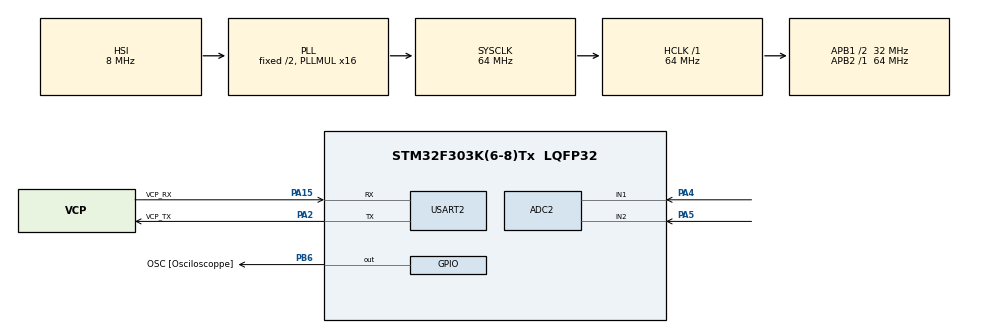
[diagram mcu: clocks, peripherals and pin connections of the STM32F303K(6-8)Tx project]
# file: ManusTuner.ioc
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ADC2.Channel-0\#ChannelRegularConversion=ADC_CHANNEL_1
ADC2.ContinuousConvMode=ENABLE
ADC2.DMAContinuousRequests=ENABLE
ADC2.NbrOfConversionFlag=1
ADC2.Offset-0\#ChannelRegularConversion=0
ADC2.OffsetNumber-0\#ChannelRegularConversion=ADC_OFFSET_NONE
ADC2.Rank-0\#ChannelRegularConversion=1
ADC2.SamplingTime-0\#ChannelRegularConversion=ADC_SAMPLETIME_61CYCLES_5
Dma.ADC2.0.Direction=DMA_PERIPH_TO_MEMORY
Dma.ADC2.0.Instance=DMA1_Channel2
Dma.ADC2.0.MemDataAlignment=DMA_MDATAALIGN_HALFWORD
Dma.ADC2.0.MemInc=DMA_MINC_ENABLE
Dma.ADC2.0.Mode=DMA_CIRCULAR
Dma.ADC2.0.PeriphDataAlignment=DMA_PDATAALIGN_HALFWORD
Dma.ADC2.0.PeriphInc=DMA_PINC_DISABLE
Dma.ADC2.0.Priority=DMA_PRIORITY_HIGH
Dma.Request0=ADC2
Mcu.Family=STM32F3
Mcu.Name=STM32F303K(6-8)Tx
Mcu.Package=LQFP32
NVIC.DMA1_Channel2_IRQn=true\:0\:0\:false\:false\:true\:false\:true
NVIC.PriorityGroup=NVIC_PRIORITYGROUP_4
PA13.GPIO_Label=SWDIO
PA13.Mode=Serial_Wire
PA13.Signal=SYS_JTMS-SWDIO
PA14.GPIO_Label=SWCLK
PA14.Mode=Serial_Wire
PA14.Signal=SYS_JTCK-SWCLK
PA15.GPIO_Label=VCP_RX
PA15.Mode=Asynchronous
PA15.Signal=USART2_RX
PA2.GPIO_Label=VCP_TX
PA2.Mode=Asynchronous
PA2.Signal=USART2_TX
PA4.Mode=IN1-Single-Ended
PA4.Signal=ADC2_IN1
PA5.Mode=IN2-Single-Ended
PA5.Signal=ADC2_IN2
PB6.GPIO_Label=OSC [Osciloscoppe]
PB6.Signal=GPIO_Output
PF0\ /\ OSC_IN.GPIO_Label=MCO
PF0\ /\ OSC_IN.Mode=HSE-External-Clock-Source
PF0\ /\ OSC_IN.Signal=RCC_OSC_IN
ProjectManager.HeapSize=0x200
ProjectManager.StackSize=0x400
ProjectManager.TargetToolchain=STM32CubeIDE
RCC.ADC12PRES=RCC_ADC12PLLCLK_DIV256
RCC.AHBFreq_Value=64000000
RCC.APB1CLKDivider=RCC_HCLK_DIV2
RCC.APB1Freq_Value=32000000
RCC.APB1TimFreq_Value=64000000
RCC.APB2Freq_Value=64000000
RCC.APB2TimFreq_Value=64000000
RCC.CortexFreq_Value=64000000
RCC.HCLKFreq_Value=64000000
RCC.HSI_VALUE=8000000
RCC.PLLMUL=RCC_PLL_MUL16
RCC.SYSCLKFreq_VALUE=64000000
RCC.SYSCLKSourceVirtual=RCC_SYSCLKSOURCE_PLLCLK
USART2.VirtualMode-Asynchronous=VM_ASYNC
board=NUCLEO-F303K8

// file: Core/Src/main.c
/* USER CODE BEGIN Header */
/**
  ******************************************************************************
  * @file           : main.c
  * @brief          : Main program body
  ******************************************************************************
  * @attention
  *
  * <h2><center>&copy; Copyright (c) 2021 STMicroelectronics.
  * All rights reserved.</center></h2>
  *
  * This software component is licensed by ST under BSD 3-Clause license,
  * the "License"; You may not use this file except in compliance with the
  * License. You may obtain a copy of the License at:
  *                        opensource.org/licenses/BSD-3-Clause
  *
  ******************************************************************************
  */
/* USER CODE END Header */
#include "main.h"
#include "adc.h"
#include "dma.h"
#include "usart.h"
#include "gpio.h"

/* USER CODE BEGIN PD */
//#define SINGLE_CONV_SAMPLES	14112u
#define SINGLE_CONV_SAMPLES	1000u
#define DMA_ADC_BUFFER_LEN	(SINGLE_CONV_SAMPLES * 2u)
/* USER CODE END PD */

/* USER CODE BEGIN PV */
uint16_t dma_adc_buff[DMA_ADC_BUFFER_LEN];
/* USER CODE END PV */

void SystemClock_Config(void);

int main(void)
{

  /* MCU Configuration--------------------------------------------------------*/

  /* Reset of all peripherals, Initializes the Flash interface and the Systick. */
  HAL_Init();

  /* Configure the system clock */
  SystemClock_Config();

  /* Initialize all configured peripherals */
  MX_GPIO_Init();
  MX_USART2_UART_Init();
  MX_DMA_Init();
  MX_ADC2_Init();
  /* USER CODE BEGIN 2 */
  HAL_ADC_Start_DMA(&hadc2, (uint32_t*)dma_adc_buff, sizeof(dma_adc_buff));
  /* USER CODE END 2 */

  /* Infinite loop */
  while (1)
  {

  }
}

void SystemClock_Config(void)
{
  RCC_OscInitTypeDef RCC_OscInitStruct = {0};
  RCC_ClkInitTypeDef RCC_ClkInitStruct = {0};
  RCC_PeriphCLKInitTypeDef PeriphClkInit = {0};

  /** Initializes the RCC Oscillators according to the specified parameters
  * in the RCC_OscInitTypeDef structure.
  */
  RCC_OscInitStruct.OscillatorType = RCC_OSCILLATORTYPE_HSI;
  RCC_OscInitStruct.HSIState = RCC_HSI_ON;
  RCC_OscInitStruct.HSICalibrationValue = RCC_HSICALIBRATION_DEFAULT;
  RCC_OscInitStruct.PLL.PLLState = RCC_PLL_ON;
  RCC_OscInitStruct.PLL.PLLSource = RCC_PLLSOURCE_HSI;
  RCC_OscInitStruct.PLL.PLLMUL = RCC_PLL_MUL16;
  if (HAL_RCC_OscConfig(&RCC_OscInitStruct) != HAL_OK)
  {
    Error_Handler();
  }
  /** Initializes the CPU, AHB and APB buses clocks
  */
  RCC_ClkInitStruct.ClockType = RCC_CLOCKTYPE_HCLK|RCC_CLOCKTYPE_SYSCLK
                              |RCC_CLOCKTYPE_PCLK1|RCC_CLOCKTYPE_PCLK2;
  RCC_ClkInitStruct.SYSCLKSource = RCC_SYSCLKSOURCE_PLLCLK;
  RCC_ClkInitStruct.AHBCLKDivider = RCC_SYSCLK_DIV1;
  RCC_ClkInitStruct.APB1CLKDivider = RCC_HCLK_DIV2;
  RCC_ClkInitStruct.APB2CLKDivider = RCC_HCLK_DIV1;

  if (HAL_RCC_ClockConfig(&RCC_ClkInitStruct, FLASH_LATENCY_2) != HAL_OK)
  {
    Error_Handler();
  }
  PeriphClkInit.PeriphClockSelection = RCC_PERIPHCLK_ADC12;
  PeriphClkInit.Adc12ClockSelection = RCC_ADC12PLLCLK_DIV256;
  if (HAL_RCCEx_PeriphCLKConfig(&PeriphClkInit) != HAL_OK)
  {
    Error_Handler();
  }
}

/* USER CODE BEGIN 4 */
void HAL_ADC_ConvHalfCpltCallback(ADC_HandleTypeDef* hadc)
{
	HAL_GPIO_WritePin(OSC_GPIO_Port, OSC_Pin, GPIO_PIN_SET);
}

void HAL_ADC_ConvCpltCallback(ADC_HandleTypeDef* hadc)
{
	HAL_GPIO_WritePin(OSC_GPIO_Port, OSC_Pin, GPIO_PIN_RESET);
}

/* USER CODE END 4 */

void Error_Handler(void)
{
  __disable_irq();
  while (1)
  {
  }
}

/************************ (C) COPYRIGHT STMicroelectronics *****END OF FILE****/
